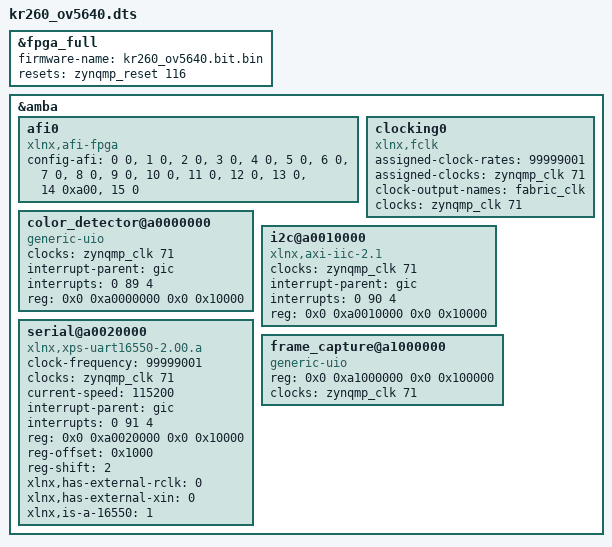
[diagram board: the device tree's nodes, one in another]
/dts-v1/;
/plugin/;

/ {
    fragment@0 {
        target = <&fpga_full>;
        __overlay__ {
            #address-cells = <2>;
            #size-cells = <2>;
            firmware-name = "kr260_ov5640.bit.bin";
            resets = <&zynqmp_reset 116>;
        };
    };

    fragment@1 {
        target = <&amba>;
        __overlay__ {
            afi0 {
                compatible = "xlnx,afi-fpga";
                config-afi = <0 0>, <1 0>, <2 0>, <3 0>,
                             <4 0>, <5 0>, <6 0>, <7 0>,
                             <8 0>, <9 0>, <10 0>, <11 0>,
                             <12 0>, <13 0>, <14 0xa00>, <15 0>;
            };

            clocking0 {
                #clock-cells = <0>;
                assigned-clock-rates = <99999001>;
                assigned-clocks = <&zynqmp_clk 71>;
                clock-output-names = "fabric_clk";
                clocks = <&zynqmp_clk 71>;
                compatible = "xlnx,fclk";
            };
        };
    };

    fragment@2 {
        target = <&amba>;
        __overlay__ {
            #address-cells = <2>;
            #size-cells = <2>;

            color_detector@a0000000 {
                compatible = "generic-uio";
                clock-names = "s_axi_aclk";
                clocks = <&zynqmp_clk 71>;
                interrupt-parent = <&gic>;
                interrupts = <0 89 4>;
                reg = <0x0 0xa0000000 0x0 0x10000>;
            };

            i2c@a0010000 {
                #address-cells = <1>;
                #size-cells = <0>;
                clock-names = "s_axi_aclk";
                clocks = <&zynqmp_clk 71>;
                compatible = "xlnx,axi-iic-2.1", "xlnx,xps-iic-2.00.a";
                interrupt-parent = <&gic>;
                interrupts = <0 90 4>;
                reg = <0x0 0xa0010000 0x0 0x10000>;
            };

            serial@a0020000 {
                clock-frequency = <99999001>;
                clock-names = "s_axi_aclk";
                clocks = <&zynqmp_clk 71>;
                compatible = "xlnx,xps-uart16550-2.00.a", "ns16550a";
                current-speed = <115200>;
                device_type = "serial";
                interrupt-parent = <&gic>;
                interrupts = <0 91 4>;
                reg = <0x0 0xa0020000 0x0 0x10000>;
                reg-offset = <0x1000>;
                reg-shift = <2>;
                xlnx,has-external-rclk = <0>;
                xlnx,has-external-xin = <0>;
                xlnx,is-a-16550 = <1>;
            };

            frame_capture@a1000000 {
                compatible = "generic-uio";
                reg = <0x0 0xa1000000 0x0 0x100000>;
                clock-names = "s_axi_aclk";
                clocks = <&zynqmp_clk 71>;
            };
        };
    };
};
